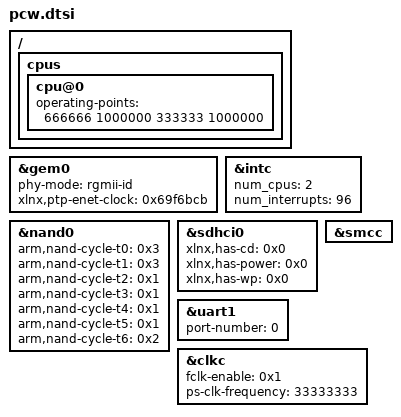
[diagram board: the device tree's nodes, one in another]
/*
 * CAUTION: This file is automatically generated by Xilinx.
 * Version:  
 * Today is: Sun Oct 27 12:55:44 2024
*/


/ {
	cpus {
		cpu@0 {
			operating-points = <666666 1000000 333333 1000000>;
		};
	};
};
&gem0 {
	phy-mode = "rgmii-id";
	status = "okay";
	xlnx,ptp-enet-clock = <0x69f6bcb>;
};
&intc {
	num_cpus = <2>;
	num_interrupts = <96>;
};
&nand0 {
	arm,nand-cycle-t0 = <0x3>;
	arm,nand-cycle-t1 = <0x3>;
	arm,nand-cycle-t2 = <0x1>;
	arm,nand-cycle-t3 = <0x1>;
	arm,nand-cycle-t4 = <0x1>;
	arm,nand-cycle-t5 = <0x1>;
	arm,nand-cycle-t6 = <0x2>;
	status = "okay";
};
&sdhci0 {
	status = "okay";
	xlnx,has-cd = <0x0>;
	xlnx,has-power = <0x0>;
	xlnx,has-wp = <0x0>;
};
&smcc {
	status = "okay";
};
&uart1 {
	device_type = "serial";
	port-number = <0>;
	status = "okay";
};
&clkc {
	fclk-enable = <0x1>;
	ps-clk-frequency = <33333333>;
};
